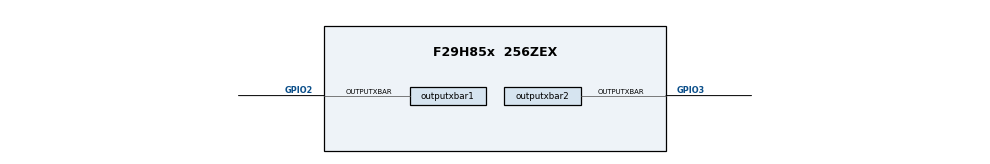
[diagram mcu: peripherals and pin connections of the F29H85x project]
/**
 * @cliArgs --device "F29H85x" --package "256ZEX" --part "F29H85x_256ZEX" --context "CPU1" --product "MCU_SDK_F29H85x@1.00.00.00"
 * @versions {"tool":"1.22.0+3877"}
 */

const divider15       = system.clockTree["PLL_REFDIV"];
divider15.divideValue = 1;

const multiplier1         = system.clockTree["PLL_IMULT"];
multiplier1.multiplyValue = 40;

const mux7       = system.clockTree["OSCCLKSRCSEL"];
mux7.inputSelect = "INTOSC2";

/**
 * Import the modules used in this configuration.
 */
const ecap        = scripting.addModule("/driverlib/ecap.js", {}, false);
const ecap1       = ecap.addInstance();
const ecap2       = ecap.addInstance();
const outputxbar  = scripting.addModule("/driverlib/outputxbar.js", {}, false);
const outputxbar1 = outputxbar.addInstance();
const outputxbar2 = outputxbar.addInstance();
const jtag        = scripting.addModule("/driverlib/jtag.js");
/**
 * Write custom configuration values to the imported modules.
 */
ecap1.$name              = "myECAP0";
ecap1.ecapMode           = "APWM";
ecap1.syncOutMode        = "ECAP_SYNC_OUT_COUNTER_PRD";
ecap1.apwmPolarity       = "ECAP_APWM_ACTIVE_LOW";
ecap1.apwmPeriod         = 20000;
ecap1.apwmCompare        = 10000;
ecap1.periphClock.$name  = "driverlib_perClock0";
ecap1.periphConfig.$name = "driverlib_perConfig0";

ecap2.ecapMode                            = "APWM";
ecap2.syncOutMode                         = "ECAP_SYNC_OUT_COUNTER_PRD";
ecap2.apwmPolarity                        = "ECAP_APWM_ACTIVE_LOW";
ecap2.apwmPeriod                          = 20000;
ecap2.apwmCompare                         = 10000;
ecap2.ecapBase                            = "ECAP2_BASE";
ecap2.phaseShiftCount                     = 6000;
ecap2.syncInPulseSource                   = "ECAP_SYNC_IN_PULSE_SRC_SYNCOUT_ECAP1";
ecap2.$name                               = "myECAP1";
ecap2.periphClock.pinmuxPeripheralModule  = scripting.forceWrite("");
ecap2.periphClock.$name                   = "driverlib_perClock0_COPY";
ecap2.periphConfig.pinmuxPeripheralModule = scripting.forceWrite("");
ecap2.periphConfig.$name                  = "driverlib_perConfig0_COPY";

outputxbar1.$name                            = "myOUTPUTXBAR0";
outputxbar1.sourceSignals                    = ["ECAP1_OUT"];
outputxbar1.outputxbar.$assign               = "OUTPUTXBAR1";
outputxbar1.outputxbar.outputxbarPin.$assign = "GPIO2";

outputxbar2.$name                            = "myOUTPUTXBAR1";
outputxbar2.sourceSignals                    = ["ECAP2_OUT"];
outputxbar2.outputxbar.$assign               = "OUTPUTXBAR2";
outputxbar2.outputxbar.outputxbarPin.$assign = "GPIO3";
